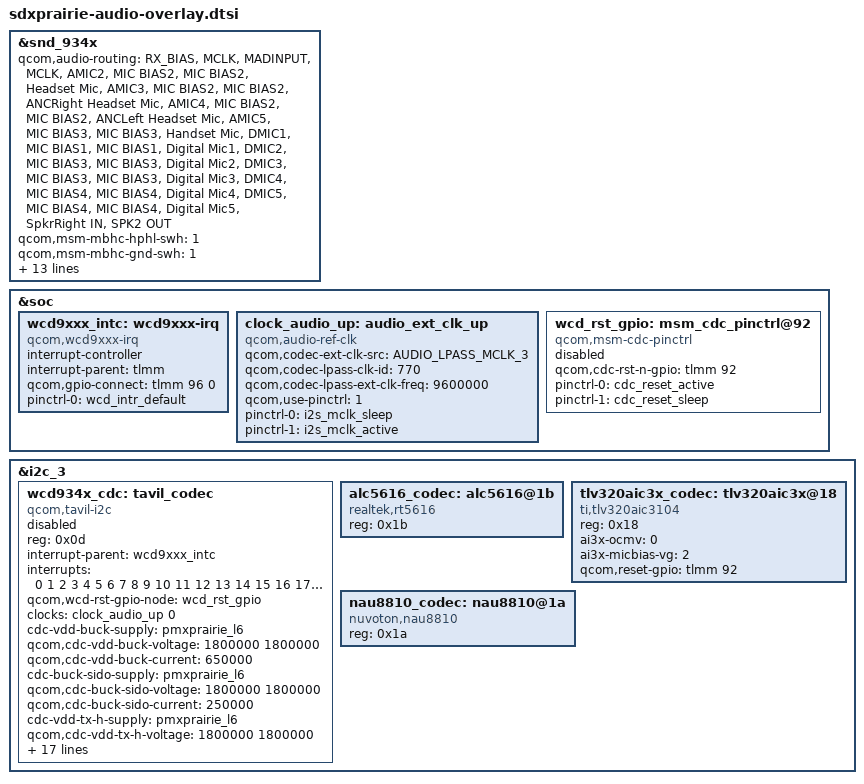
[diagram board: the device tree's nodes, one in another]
/*
 * Copyright (c) 2017-2019, The Linux Foundation. All rights reserved.
 *
 * This program is free software; you can redistribute it and/or modify
 * it under the terms of the GNU General Public License version 2 and
 * only version 2 as published by the Free Software Foundation.
 *
 * This program is distributed in the hope that it will be useful,
 * but WITHOUT ANY WARRANTY; without even the implied warranty of
 * MERCHANTABILITY or FITNESS FOR A PARTICULAR PURPOSE.  See the
 * GNU General Public License for more details.
 */
/*==========================================================================
  WHEN          WHO                          WHY
-----------  -----------  --------------------------------------------------
 2019/10/17   augus.xiong          support audio bring up
===========================================================================*/
#include "sdxprairie-wcd.dtsi"
#include "sdx-wsa881x.dtsi"
#include <dt-bindings/clock/qcom,audio-ext-clk.h>

&snd_934x {
	qcom,audio-routing =
		"RX_BIAS", "MCLK",
		"MADINPUT", "MCLK",
		"AMIC2", "MIC BIAS2",
		"MIC BIAS2", "Headset Mic",
		"AMIC3", "MIC BIAS2",
		"MIC BIAS2", "ANCRight Headset Mic",
		"AMIC4", "MIC BIAS2",
		"MIC BIAS2", "ANCLeft Headset Mic",
		"AMIC5", "MIC BIAS3",
		"MIC BIAS3", "Handset Mic",
		"DMIC1", "MIC BIAS1",
		"MIC BIAS1", "Digital Mic1",
		"DMIC2", "MIC BIAS3",
		"MIC BIAS3", "Digital Mic2",
		"DMIC3", "MIC BIAS3",
		"MIC BIAS3", "Digital Mic3",
		"DMIC4", "MIC BIAS4",
		"MIC BIAS4", "Digital Mic4",
		"DMIC5", "MIC BIAS4",
		"MIC BIAS4", "Digital Mic5",
		"SpkrRight IN", "SPK2 OUT";

	qcom,msm-mbhc-hphl-swh = <1>;
	qcom,msm-mbhc-gnd-swh = <1>;
	qcom,msm-mbhc-hs-mic-max-threshold-mv = <1700>;
	qcom,msm-mbhc-hs-mic-min-threshold-mv = <50>;
//2019/10/17 add by augus for audio bring up
        qcom,tavil-mclk-clk-freq = <12288000>; 

        asoc-codec = <&stub_codec>,<&nau8810_codec>, <&tlv320aic3x_codec>,<&alc5616_codec>;
        asoc-codec-names = "msm-stub-codec.1","nau8810.3-001a", "tlv320aic3x-codec.3-0018","alc5616-codec.3-001b";
//end augus
	qcom,wsa-max-devs = <2>;
	qcom,wsa-devs = <&wsa881x_0211>, <&wsa881x_0212>,
			<&wsa881x_0213>, <&wsa881x_0214>;
	qcom,wsa-aux-dev-prefix = "SpkrLeft", "SpkrRight",
				  "SpkrLeft", "SpkrRight";
};

&soc {
	wcd9xxx_intc: wcd9xxx-irq {
		status = "ok";
		compatible = "qcom,wcd9xxx-irq";
		interrupt-controller;
		#interrupt-cells = <1>;
		interrupt-parent = <&tlmm>;
		qcom,gpio-connect = <&tlmm 96 0>;
		pinctrl-names = "default";
		pinctrl-0 = <&wcd_intr_default>;
	};

	clock_audio_up: audio_ext_clk_up {
		compatible = "qcom,audio-ref-clk";
		qcom,codec-ext-clk-src = <AUDIO_LPASS_MCLK_3>;
		qcom,codec-lpass-clk-id = <770>;
		qcom,codec-lpass-ext-clk-freq = <9600000>;
		qcom,use-pinctrl = <1>;
		pinctrl-names = "sleep", "active";
		pinctrl-0 = <&i2s_mclk_sleep>;
		pinctrl-1 = <&i2s_mclk_active>;
		#clock-cells = <1>;
	};

	wcd_rst_gpio: msm_cdc_pinctrl@92 {
		status = "disabled";
		compatible = "qcom,msm-cdc-pinctrl";
		qcom,cdc-rst-n-gpio = <&tlmm 92 0>;
		pinctrl-names = "aud_active", "aud_sleep";
		pinctrl-0 = <&cdc_reset_active>;
		pinctrl-1 = <&cdc_reset_sleep>;
	};
};

&i2c_3 {
	wcd934x_cdc: tavil_codec {
		compatible = "qcom,tavil-i2c";
		reg = <0x0d>;

		interrupt-parent = <&wcd9xxx_intc>;
		interrupts = <0 1 2 3 4 5 6 7 8 9 10 11 12 13 14 15 16
			      17 18 19 20 21 22 23 24 25 26 27 28 29
			      30 31>;

		qcom,wcd-rst-gpio-node = <&wcd_rst_gpio>;

		clock-names = "wcd_clk";
		clocks = <&clock_audio_up 0>;

		cdc-vdd-buck-supply = <&pmxprairie_l6>;
		qcom,cdc-vdd-buck-voltage = <1800000 1800000>;
		qcom,cdc-vdd-buck-current = <650000>;

		cdc-buck-sido-supply = <&pmxprairie_l6>;
		qcom,cdc-buck-sido-voltage = <1800000 1800000>;
		qcom,cdc-buck-sido-current = <250000>;

		cdc-vdd-tx-h-supply = <&pmxprairie_l6>;
		qcom,cdc-vdd-tx-h-voltage = <1800000 1800000>;
		qcom,cdc-vdd-tx-h-current = <25000>;

		cdc-vdd-rx-h-supply = <&pmxprairie_l6>;
		qcom,cdc-vdd-rx-h-voltage = <1800000 1800000>;
		qcom,cdc-vdd-rx-h-current = <25000>;

		cdc-vddpx-1-supply = <&pmxprairie_l6>;
		qcom,cdc-vddpx-1-voltage = <1800000 1800000>;
		qcom,cdc-vddpx-1-current = <10000>;

		qcom,cdc-static-supplies = "cdc-vdd-buck",
					   "cdc-buck-sido",
					   "cdc-vdd-tx-h",
					   "cdc-vdd-rx-h",
					   "cdc-vddpx-1";

		qcom,cdc-micbias1-mv = <1800>;
		qcom,cdc-micbias2-mv = <1800>;
		qcom,cdc-micbias3-mv = <1800>;
		qcom,cdc-micbias4-mv = <1800>;

		qcom,cdc-mclk-clk-rate = <9600000>;
		qcom,cdc-dmic-sample-rate = <4800000>;

		qcom,wdsp-cmpnt-dev-name = "tavil_codec";
		status = "disabled";  //modified by baker:20191106 remove too many i2c error info in debug log
	};
//2019/010/17 add by augus for audio bring up
        alc5616_codec: alc5616@1b{

                compatible = "realtek,rt5616";
                reg = <0x1b>;

        };
        tlv320aic3x_codec: tlv320aic3x@18{
                compatible = "ti,tlv320aic3104";
                reg = <0x18>;
                ai3x-ocmv = <0>;
                ai3x-micbias-vg = <2>;
		qcom,reset-gpio = <&tlmm 92 0>;		//larryzhang-20200417: add codec reset pin
        };

        nau8810_codec: nau8810@1a{
                compatible = "nuvoton,nau8810";
                reg = <0x1a>;
        };
//end augus


};
